VERSION ""

NS_ :

BS_:

BU_:

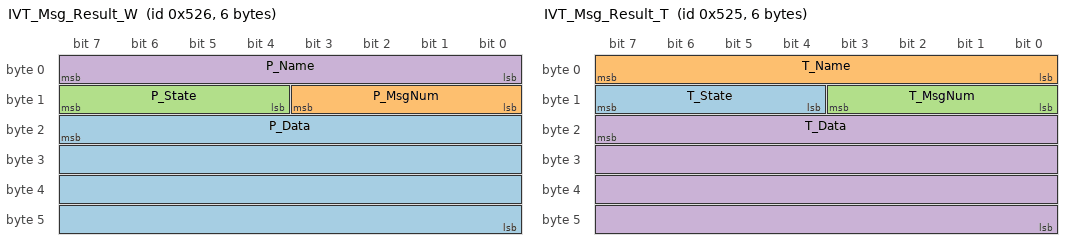
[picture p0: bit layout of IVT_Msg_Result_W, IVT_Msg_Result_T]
BO_ 1318 IVT_Msg_Result_W: 6 Vector__XXX
 SG_ P_Data : 23|32@0- (1,0) [0|0] "W" Vector__XXX
 SG_ P_MsgNum : 11|4@0+ (1,0) [0|0] "" Vector__XXX
 SG_ P_State : 15|4@0+ (1,0) [0|0] "" Vector__XXX
 SG_ P_Name : 7|8@0+ (1,0) [0|0] "" Vector__XXX

BO_ 1317 IVT_Msg_Result_T: 6 Vector__XXX
 SG_ T_State : 15|4@0+ (1,0) [0|0] "" Vector__XXX
 SG_ T_Name : 7|8@0+ (1,0) [0|0] "" Vector__XXX
 SG_ T_MsgNum : 11|4@0+ (1,0) [0|0] "" Vector__XXX
 SG_ T_Data : 23|32@0- (0.1,0) [0|0] "°„C" Vector__XXX

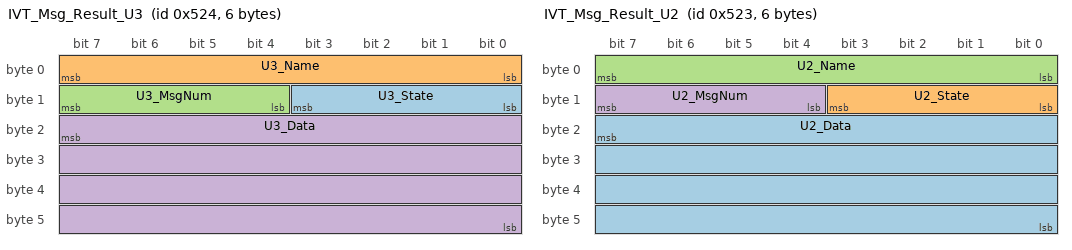
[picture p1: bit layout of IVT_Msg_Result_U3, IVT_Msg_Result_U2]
BO_ 1316 IVT_Msg_Result_U3: 6 Vector__XXX
 SG_ U3_State : 11|4@0+ (1,0) [0|0] "" Vector__XXX
 SG_ U3_Name : 7|8@0+ (1,0) [0|0] "" Vector__XXX
 SG_ U3_MsgNum : 15|4@0+ (1,0) [0|0] "" Vector__XXX
 SG_ U3_Data : 23|32@0+ (0.001,0) [0|0] "V" Vector__XXX

BO_ 1315 IVT_Msg_Result_U2: 6 Vector__XXX
 SG_ U2_Data : 23|32@0- (0.001,0) [-1000|1000] "V" Vector__XXX
 SG_ U2_State : 11|4@0+ (1,0) [0|0] "" Vector__XXX
 SG_ U2_Name : 7|8@0+ (1,0) [0|0] "" Vector__XXX
 SG_ U2_MsgNum : 15|4@0+ (1,0) [0|0] "" Vector__XXX

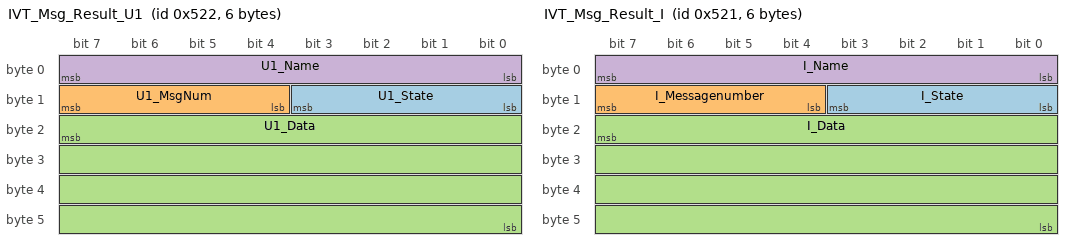
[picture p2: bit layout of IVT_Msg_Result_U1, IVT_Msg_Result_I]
BO_ 1314 IVT_Msg_Result_U1: 6 Vector__XXX
 SG_ U1_State : 11|4@0+ (1,0) [0|0] "" Vector__XXX
 SG_ U1_MsgNum : 15|4@0+ (1,0) [0|0] "" Vector__XXX
 SG_ U1_Data : 23|32@0- (0.001,0) [-1000|1000] "V" Vector__XXX
 SG_ U1_Name : 7|8@0+ (1,0) [0|0] "" Vector__XXX

BO_ 1313 IVT_Msg_Result_I: 6 Vector__XXX
 SG_ I_State : 11|4@0+ (1,0) [0|0] "" Vector__XXX
 SG_ I_Messagenumber : 15|4@0+ (1,0) [0|0] "" Vector__XXX
 SG_ I_Data : 23|32@0- (0.001,0) [0|0] "A" Vector__XXX
 SG_ I_Name : 7|8@0+ (1,0) [0|0] "" Vector__XXX
